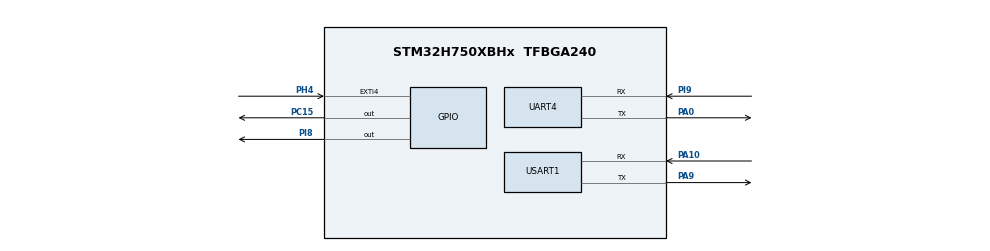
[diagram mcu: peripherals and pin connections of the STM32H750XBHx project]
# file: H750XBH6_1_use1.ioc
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CORTEX_M7.CPU_DCache=Enabled
CORTEX_M7.CPU_ICache=Enabled
Mcu.Family=STM32H7
Mcu.Name=STM32H750XBHx
Mcu.Package=TFBGA240
NVIC.EXTI4_IRQn=true\:2\:0\:true\:false\:true\:true\:true
NVIC.PriorityGroup=NVIC_PRIORITYGROUP_4
NVIC.UART4_IRQn=true\:0\:0\:false\:false\:true\:true\:true
PA0.Mode=Asynchronous
PA0.Signal=UART4_TX
PA10.Mode=Asynchronous
PA10.Signal=USART1_RX
PA13\ (JTMS/SWDIO).Mode=Serial_Wire
PA13\ (JTMS/SWDIO).Signal=DEBUG_JTMS-SWDIO
PA14\ (JTCK/SWCLK).Mode=Serial_Wire
PA14\ (JTCK/SWCLK).Signal=DEBUG_JTCK-SWCLK
PA9.Mode=Asynchronous
PA9.Signal=USART1_TX
PC15-OSC32_OUT\ (OSC32_OUT).Signal=GPIO_Output
PH0-OSC_IN\ (PH0).Mode=HSE-External-Oscillator
PH0-OSC_IN\ (PH0).Signal=RCC_OSC_IN
PH1-OSC_OUT\ (PH1).Mode=HSE-External-Oscillator
PH1-OSC_OUT\ (PH1).Signal=RCC_OSC_OUT
PH4.GPIO_ModeDefaultEXTI=GPIO_MODE_IT_FALLING
PH4.GPIO_PuPd=GPIO_PULLUP
PH4.Signal=GPXTI4
PI8.Signal=GPIO_Output
PI9.Mode=Asynchronous
PI9.Signal=UART4_RX
ProjectManager.HeapSize=0x200
ProjectManager.StackSize=0x400
ProjectManager.TargetToolchain=MDK-ARM V5.27
RCC.ADCFreq_Value=129000000
RCC.APB1Freq_Value=120000000
RCC.APB2Freq_Value=120000000
RCC.APB3Freq_Value=120000000
RCC.APB4Freq_Value=120000000
RCC.CortexFreq_Value=480000000
RCC.D1PPRE=RCC_APB3_DIV2
RCC.D2PPRE1=RCC_APB1_DIV2
RCC.D2PPRE2=RCC_APB2_DIV2
RCC.D3PPRE=RCC_APB4_DIV2
RCC.DIVM1=4
RCC.DIVN1=60
RCC.HCLKFreq_Value=240000000
RCC.HPRE=RCC_HCLK_DIV2
RCC.PLL2FRACN=0
RCC.PLL3FRACN=0
RCC.PLLFRACN=0
RCC.SYSCLKFreq_VALUE=480000000
RCC.SYSCLKSource=RCC_SYSCLKSOURCE_PLLCLK
RCC.USBFreq_Value=480000000
USART1.VirtualMode-Asynchronous=VM_ASYNC
board=custom

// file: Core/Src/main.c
/* USER CODE BEGIN Header */
/**
  ******************************************************************************
  * @file           : main.c
  * @brief          : Main program body
  ******************************************************************************
  * @attention
  *
  * <h2><center>&copy; Copyright (c) 2023 STMicroelectronics.
  * All rights reserved.</center></h2>
  *
  * This software component is licensed by ST under BSD 3-Clause license,
  * the "License"; You may not use this file except in compliance with the
  * License. You may obtain a copy of the License at:
  *                        opensource.org/licenses/BSD-3-Clause
  *
  ******************************************************************************
  */
/* USER CODE END Header */
#include "main.h"
#include "usart.h"
#include "gpio.h"

/* USER CODE BEGIN Includes */
#include <stdio.h>
/* USER CODE END Includes */

void SystemClock_Config(void);

int main(void)
{
  /* USER CODE BEGIN 1 */
    char a[]="���";
  /* USER CODE END 1 */

  /* Enable I-Cache---------------------------------------------------------*/
  SCB_EnableICache();

  /* Enable D-Cache---------------------------------------------------------*/
  SCB_EnableDCache();

  /* MCU Configuration--------------------------------------------------------*/

  /* Reset of all peripherals, Initializes the Flash interface and the Systick. */
  HAL_Init();

  /* Configure the system clock */
  SystemClock_Config();

  /* Initialize all configured peripherals */
  MX_GPIO_Init();
  MX_USART1_UART_Init();
  MX_UART4_Init();
  /* USER CODE BEGIN 2 */
    GPIOC->ODR^=GPIO_PIN_15;
    GPIOI->ODR^=GPIO_PIN_8;
    HAL_UART_Transmit(&huart1,(uint8_t*)a,1,100);
  /* USER CODE END 2 */

  /* Infinite loop */
  while (1)
  {

    /* USER CODE BEGIN 3 */
      GPIOC->ODR^=GPIO_PIN_15;
      HAL_Delay(1000);
      printf("���\n");
  }
  /* USER CODE END 3 */
}

void SystemClock_Config(void)
{
  RCC_OscInitTypeDef RCC_OscInitStruct = {0};
  RCC_ClkInitTypeDef RCC_ClkInitStruct = {0};
  RCC_PeriphCLKInitTypeDef PeriphClkInitStruct = {0};

  /** Supply configuration update enable
  */
  HAL_PWREx_ConfigSupply(PWR_LDO_SUPPLY);
  /** Configure the main internal regulator output voltage
  */
  __HAL_PWR_VOLTAGESCALING_CONFIG(PWR_REGULATOR_VOLTAGE_SCALE0);

  while(!__HAL_PWR_GET_FLAG(PWR_FLAG_VOSRDY)) {}
  /** Initializes the RCC Oscillators according to the specified parameters
  * in the RCC_OscInitTypeDef structure.
  */
  RCC_OscInitStruct.OscillatorType = RCC_OSCILLATORTYPE_HSI;
  RCC_OscInitStruct.HSIState = RCC_HSI_DIV1;
  RCC_OscInitStruct.HSICalibrationValue = RCC_HSICALIBRATION_DEFAULT;
  RCC_OscInitStruct.PLL.PLLState = RCC_PLL_ON;
  RCC_OscInitStruct.PLL.PLLSource = RCC_PLLSOURCE_HSI;
  RCC_OscInitStruct.PLL.PLLM = 4;
  RCC_OscInitStruct.PLL.PLLN = 60;
  RCC_OscInitStruct.PLL.PLLP = 2;
  RCC_OscInitStruct.PLL.PLLQ = 2;
  RCC_OscInitStruct.PLL.PLLR = 2;
  RCC_OscInitStruct.PLL.PLLRGE = RCC_PLL1VCIRANGE_3;
  RCC_OscInitStruct.PLL.PLLVCOSEL = RCC_PLL1VCOWIDE;
  RCC_OscInitStruct.PLL.PLLFRACN = 0;
  if (HAL_RCC_OscConfig(&RCC_OscInitStruct) != HAL_OK)
  {
    Error_Handler();
  }
  /** Initializes the CPU, AHB and APB buses clocks
  */
  RCC_ClkInitStruct.ClockType = RCC_CLOCKTYPE_HCLK|RCC_CLOCKTYPE_SYSCLK
                              |RCC_CLOCKTYPE_PCLK1|RCC_CLOCKTYPE_PCLK2
                              |RCC_CLOCKTYPE_D3PCLK1|RCC_CLOCKTYPE_D1PCLK1;
  RCC_ClkInitStruct.SYSCLKSource = RCC_SYSCLKSOURCE_PLLCLK;
  RCC_ClkInitStruct.SYSCLKDivider = RCC_SYSCLK_DIV1;
  RCC_ClkInitStruct.AHBCLKDivider = RCC_HCLK_DIV2;
  RCC_ClkInitStruct.APB3CLKDivider = RCC_APB3_DIV2;
  RCC_ClkInitStruct.APB1CLKDivider = RCC_APB1_DIV2;
  RCC_ClkInitStruct.APB2CLKDivider = RCC_APB2_DIV2;
  RCC_ClkInitStruct.APB4CLKDivider = RCC_APB4_DIV2;

  if (HAL_RCC_ClockConfig(&RCC_ClkInitStruct, FLASH_LATENCY_4) != HAL_OK)
  {
    Error_Handler();
  }
  PeriphClkInitStruct.PeriphClockSelection = RCC_PERIPHCLK_UART4|RCC_PERIPHCLK_USART1;
  PeriphClkInitStruct.Usart234578ClockSelection = RCC_USART234578CLKSOURCE_D2PCLK1;
  PeriphClkInitStruct.Usart16ClockSelection = RCC_USART16CLKSOURCE_D2PCLK2;
  if (HAL_RCCEx_PeriphCLKConfig(&PeriphClkInitStruct) != HAL_OK)
  {
    Error_Handler();
  }
}

void Error_Handler(void)
{
  __disable_irq();
  while (1)
  {
  }
}

/************************ (C) COPYRIGHT STMicroelectronics *****END OF FILE****/
